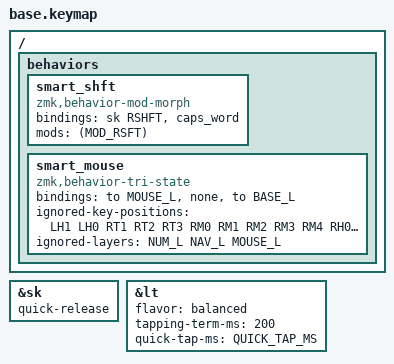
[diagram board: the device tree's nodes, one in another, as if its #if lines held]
// forked from https://github.com/urob/zmk-config/blob/9f386d209657a1aefc625633bda13f5a091ea465/config/base.keymap
#include <behaviors.dtsi>
#include <behaviors/num_word.dtsi> // Requires zmk-auto-layer module.
#include <dt-bindings/zmk/keys.h>
#ifdef CONFIG_WIRELESS
  #include <dt-bindings/zmk/bt.h>
  #include <dt-bindings/zmk/outputs.h>
  #define _BT_SEL_KEYS_ \
      &bt BT_SEL 0 &bt BT_SEL 1 &bt BT_SEL 2 &bt BT_SEL 3 &bt BT_CLR
#else
  #define _BT_SEL_KEYS_ &trans &trans &trans &trans &trans
#endif

#include <zmk-helpers/helper.h> // Requires zmk-helpers module.

#define BASE_L 0
#define NUM_L 1
#define NAV_L 2
#define MOUSE_L 3
#define SYS_L 4

#define XXX &none
#define ___ &trans

/* Global defaults */

#define QUICK_TAP_MS 175

&sk {
  quick-release;
};

&lt {
  flavor = "balanced";
  tapping-term-ms = <200>;
  quick-tap-ms = <QUICK_TAP_MS>;
};

// Tap: sticky-shift | Shift + tap/ double-tap: caps-word | Hold: shift.
ZMK_MOD_MORPH(smart_shft, bindings = <&sk RSHFT>, <&caps_word>;
              mods = <(MOD_RSFT)>;)

// Smart-mouse, requires tri-state module.
ZMK_TRI_STATE(smart_mouse, bindings = <&to MOUSE_L>, <&none>, <&to BASE_L>;
              ignored-key-positions = <LH1 LH0 RT1 RT2 RT3 RM0 RM1 RM2 RM3 RM4 RH0 RH1 RH2>;
              ignored-layers = <NUM_L NAV_L MOUSE_L>;)

// Misc aliases.
ZMK_BEHAVIOR(home_lc, tap_dance,
    bindings = <&kp HOME>, <&kp LC(HOME)>;)
ZMK_BEHAVIOR(end_lc, tap_dance,
    bindings = <&kp END>, <&kp LC(END)>;)
ZMK_BEHAVIOR(pp_prev, tap_dance,
    bindings = <&kp C_PP>, <&kp C_PREV>;)

#include "combos.dtsi"
#include "mouse.dtsi"

/* Keymap */
#ifndef ZMK_BASE_LAYER
  #define ZMK_BASE_LAYER(name, LT, RT, LM, RM, LB, RB, LH, RH) \
      ZMK_LAYER(name, LT RT LM RM LB RB LH RH)
#endif

ZMK_BASE_LAYER(BASE,
//╭─────────────┬─────────────┬─────────────┬─────────────┬─────────────┬─────────────╮ ╭─────────────┬─────────────┬─────────────┬─────────────┬─────────────┬─────────────╮
    &kp TAB       &kp Q         &kp W         &kp E         &kp R         &kp T       ,   &kp Y         &kp U         &kp I         &kp O         &kp P         &kp BSLH    ,
//├─────────────┼─────────────┼─────────────┼─────────────┼─────────────┼─────────────┤ ├─────────────┼─────────────┼─────────────┼─────────────┼─────────────┼─────────────┤
    &sk LCTRL     &kp A         &kp S         &kp D         &kp F         &kp G       ,   &kp H         &kp J         &kp K         &kp L         &kp SEMI      &kp APOS    ,
//├─────────────┼─────────────┼─────────────┼─────────────┼─────────────┼─────────────┤ ├─────────────┼─────────────┼─────────────┼─────────────┼─────────────┼─────────────┤
    &kp LSHFT     &kp Z         &kp X         &kp C         &kp V         &kp B       ,   &kp N         &kp M         &kp COMMA     &kp DOT       &kp SLASH     &to BASE_L  ,
//╰─────────────┼─────────────┴─────────────┼─────────────┼─────────────┼─────────────┤ ├─────────────┼─────────────┼─────────────┼─────────────┴───────────────────────────╯
                                              &sk LALT    &lt NUM_L SPACE &lt NAV_L RET,  &smart_shft   &lt NAV_L BSPC &sk RGUI
//                                          ╰─────────────┴─────────────┴─────────────╯ ╰─────────────┴─────────────┴─────────────╯
)

ZMK_BASE_LAYER(NUM,
//╭─────────────┬─────────────┬─────────────┬─────────────┬─────────────┬─────────────╮ ╭─────────────┬─────────────┬─────────────┬─────────────┬─────────────┬─────────────╮
    &kp TILDE     &kp EXCL      &kp AT        &kp HASH      &kp DLLR      &kp PRCNT   ,   &kp CARET     &kp AMPS      &kp ASTRK     &kp LPAR      &kp RPAR      ___         ,
//├─────────────┼─────────────┼─────────────┼─────────────┼─────────────┼─────────────┤ ├─────────────┼─────────────┼─────────────┼─────────────┼─────────────┼─────────────┤
    &kp GRAVE     &kp N1        &kp N2        &kp N3        &kp N4        &kp N5      ,   &kp N6        &kp N7        &kp N8        &kp N9        &kp N0        ___         ,
//├─────────────┼─────────────┼─────────────┼─────────────┼─────────────┼─────────────┤ ├─────────────┼─────────────┼─────────────┼─────────────┼─────────────┼─────────────┤
    &kp PLUS      &kp MINUS     &kp UNDER     &kp EQUAL     &kp LBRC      &kp RBRC    ,   &kp LBKT      &kp RBKT      ___           ___           ___           ___         ,
//╰─────────────┼─────────────┴─────────────┼─────────────┼─────────────┼─────────────┤ ├─────────────┼─────────────┼─────────────┼─────────────┴───────────────────────────╯
                                              ___           ___           ___         ,   ___           ___           ___
//                                          ╰─────────────┴─────────────┴─────────────╯ ╰─────────────┴─────────────┴─────────────╯
)

ZMK_BASE_LAYER(NAV,
//╭─────────────┬─────────────┬─────────────┬─────────────┬─────────────┬─────────────╮ ╭─────────────┬─────────────┬─────────────┬─────────────┬─────────────┬─────────────╮
    ___           &kp F1        &kp F2        &kp F3        &kp F4        &kp F5      ,   &kp F6        &kp F7        &kp F8        &kp F9        &kp F10       ___         ,
//├─────────────┼─────────────┼─────────────┼─────────────┼─────────────┼─────────────┤ ├─────────────┼─────────────┼─────────────┼─────────────┼─────────────┼─────────────┤
    ___           &kp F11       &kp F12       ___           ___           &kp PSCRN   ,   ___           &kp LEFT      &kp DOWN      &kp UP        &kp RIGHT     ___         ,
//├─────────────┼─────────────┼─────────────┼─────────────┼─────────────┼─────────────┤ ├─────────────┼─────────────┼─────────────┼─────────────┼─────────────┼─────────────┤
    ___           &kp C_NEXT    &kp C_MUTE    &kp C_VOL_DN  &kp C_VOL_UP  &pp_prev    ,   &kp INS       &home_lc      &kp PG_DN     &kp PG_UP     &end_lc       ___         ,
//╰─────────────┼─────────────┴─────────────┼─────────────┼─────────────┼─────────────┤ ├─────────────┼─────────────┼─────────────┼─────────────┴───────────────────────────╯
                                              ___           ___           ___         ,   ___           ___           ___
//                                          ╰─────────────┴─────────────┴─────────────╯ ╰─────────────┴─────────────┴─────────────╯
)

ZMK_BASE_LAYER(MOUSE,
//╭─────────────┬─────────────┬─────────────┬─────────────┬─────────────┬─────────────╮ ╭─────────────┬─────────────┬─────────────┬─────────────┬─────────────┬─────────────╮
    ___           ___           ___           ___           ___           ___         ,   ___           ___           ___           ___           ___           ___         ,
//├─────────────┼─────────────┼─────────────┼─────────────┼─────────────┼─────────────┤ ├─────────────┼─────────────┼─────────────┼─────────────┼─────────────┼─────────────┤
    ___           ___           ___           ___           ___           ___         ,   ___           U_MS_L        U_MS_D        U_MS_U        U_MS_R        ___         ,
//├─────────────┼─────────────┼─────────────┼─────────────┼─────────────┼─────────────┤ ├─────────────┼─────────────┼─────────────┼─────────────┼─────────────┼─────────────┤
    ___           ___           ___           ___           ___           ___         ,   ___           U_WH_L        U_WH_U        U_WH_U        U_WH_R        ___         ,
//╰─────────────┼─────────────┴─────────────┼─────────────┼─────────────┼─────────────┤ ├─────────────┼─────────────┼─────────────┼─────────────┴───────────────────────────╯
                                              ___           ___           ___         ,   &mkp MCLK     &mkp LCLK     &mkp RCLK
//                                          ╰─────────────┴─────────────┴─────────────╯ ╰─────────────┴─────────────┴─────────────╯
)

ZMK_BASE_LAYER(SYS,
//╭─────────────┬─────────────┬─────────────┬─────────────┬─────────────┬─────────────╮ ╭─────────────┬─────────────┬─────────────┬─────────────┬─────────────┬─────────────╮
    ___           _BT_SEL_KEYS_                                                       ,   ___           ___           ___           ___           ___           ___         ,
//├─────────────┼─────────────┼─────────────┼─────────────┼─────────────┼─────────────┤ ├─────────────┼─────────────┼─────────────┼─────────────┼─────────────┼─────────────┤
    ___           ___           ___           ___           ___           &bootloader ,   &bootloader   ___           ___           ___           ___           ___         ,
//├─────────────┼─────────────┼─────────────┼─────────────┼─────────────┼─────────────┤ ├─────────────┼─────────────┼─────────────┼─────────────┼─────────────┼─────────────┤
    ___           ___           ___           ___           ___           &sys_reset  ,   &sys_reset    ___           ___           ___           ___           ___         ,
//╰─────────────┼─────────────┴─────────────┼─────────────┼─────────────┼─────────────┤ ├─────────────┼─────────────┼─────────────┼─────────────┴───────────────────────────╯
                                              ___           ___           ___         ,   ___           ___           ___
//                                          ╰─────────────┴─────────────┴─────────────╯ ╰─────────────┴─────────────┴─────────────╯
)

/* vim: set ft=c tw=146: */
